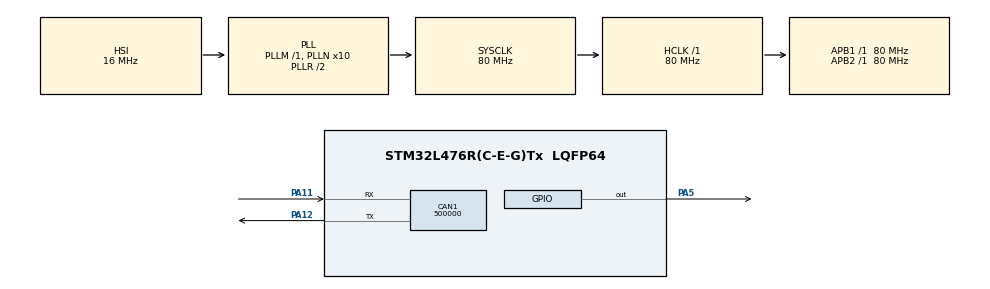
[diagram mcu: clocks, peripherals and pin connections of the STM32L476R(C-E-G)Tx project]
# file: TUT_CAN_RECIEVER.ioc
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CAN1.BS1=CAN_BS1_6TQ
CAN1.BS2=CAN_BS2_3TQ
CAN1.CalculateBaudRate=500000
CAN1.CalculateTimeBit=2000
CAN1.CalculateTimeQuantum=200.0
Mcu.Family=STM32L4
Mcu.Name=STM32L476R(C-E-G)Tx
Mcu.Package=LQFP64
NVIC.CAN1_RX0_IRQn=true\:0\:0\:false\:false\:true\:true\:true\:true
NVIC.PriorityGroup=NVIC_PRIORITYGROUP_4
PA11.Mode=CAN_Activate
PA11.Signal=CAN1_RX
PA12.Mode=CAN_Activate
PA12.Signal=CAN1_TX
PA5.Signal=GPIO_Output
PH0-OSC_IN\ (PH0).Mode=HSE-External-Oscillator
PH0-OSC_IN\ (PH0).Signal=RCC_OSC_IN
PH1-OSC_OUT\ (PH1).Mode=HSE-External-Oscillator
PH1-OSC_OUT\ (PH1).Signal=RCC_OSC_OUT
ProjectManager.HeapSize=0x200
ProjectManager.StackSize=0x400
ProjectManager.TargetToolchain=STM32CubeIDE
RCC.ADCFreq_Value=64000000
RCC.AHBFreq_Value=80000000
RCC.APB1Freq_Value=80000000
RCC.APB1TimFreq_Value=80000000
RCC.APB2Freq_Value=80000000
RCC.APB2TimFreq_Value=80000000
RCC.CortexFreq_Value=80000000
RCC.HCLKFreq_Value=80000000
RCC.HSE_VALUE=8000000
RCC.HSI_VALUE=16000000
RCC.MSI_VALUE=4000000
RCC.PLLN=10
RCC.PLLSourceVirtual=RCC_PLLSOURCE_HSI
RCC.PREFETCH_ENABLE=1
RCC.SYSCLKFreq_VALUE=80000000
RCC.SYSCLKSource=RCC_SYSCLKSOURCE_PLLCLK
RCC.USBFreq_Value=64000000
RCC.VCOOutputFreq_Value=160000000
board=NUCLEO-L476RG

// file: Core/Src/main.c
/* USER CODE BEGIN Header */
/**
  ******************************************************************************
  * @file           : main.c
  * @brief          : Main program body
  ******************************************************************************
  * @attention
  *
  * Copyright (c) 2023 STMicroelectronics.
  * All rights reserved.
  *
  * This software is licensed under terms that can be found in the LICENSE file
  * in the root directory of this software component.
  * If no LICENSE file comes with this software, it is provided AS-IS.
  *
  ******************************************************************************
  */
/* USER CODE END Header */
#include "main.h"

CAN_HandleTypeDef hcan1;

void SystemClock_Config(void);
static void MX_GPIO_Init(void);
static void MX_CAN1_Init(void);

/* USER CODE BEGIN 0 */

CAN_TxHeaderTypeDef TxHeader;
CAN_RxHeaderTypeDef RxHeader;

uint8_t TxData[8];
uint8_t RxData[8];

uint32_t TxMailbox;

int datacheck = 0;

void HAL_CAN_RxFifo0MsgPendingCallback(CAN_HandleTypeDef *hcan)
{
	HAL_CAN_GetRxMessage(hcan, CAN_RX_FIFO0, &RxHeader, RxData);
	if (RxHeader.DLC == 2)
	{
		datacheck = 1;
	}
}

/* USER CODE END 0 */

int main(void)
{

  /* MCU Configuration--------------------------------------------------------*/

  /* Reset of all peripherals, Initializes the Flash interface and the Systick. */
  HAL_Init();

  /* Configure the system clock */
  SystemClock_Config();

  /* Initialize all configured peripherals */
  MX_GPIO_Init();
  MX_CAN1_Init();
  /* USER CODE BEGIN 2 */

  HAL_CAN_Start(&hcan1);

  // Activate the notification
  HAL_CAN_ActivateNotification(&hcan1, CAN_IT_RX_FIFO0_MSG_PENDING);

  TxHeader.DLC = 2;  // data length
  TxHeader.IDE = CAN_ID_STD;
  TxHeader.RTR = CAN_RTR_DATA;
  TxHeader.StdId = 0x103;  // ID

  /* USER CODE END 2 */

  /* Infinite loop */
  while (1)
  {
	  if (datacheck)
	  {
		  // blink the LED
		  for (int i=0; i<RxData[1]; i++)
		  {
			  HAL_GPIO_TogglePin(GPIOA, GPIO_PIN_5);
			  HAL_Delay(RxData[0]);
		  }

		  datacheck = 0;

			TxData[0] = 50;   // ms Delay
			TxData[1] = 20;    // loop rep

			HAL_CAN_AddTxMessage(&hcan1, &TxHeader, TxData, &TxMailbox);
	  }
  }
}

void SystemClock_Config(void)
{
  RCC_OscInitTypeDef RCC_OscInitStruct = {0};
  RCC_ClkInitTypeDef RCC_ClkInitStruct = {0};

  /** Configure the main internal regulator output voltage
  */
  if (HAL_PWREx_ControlVoltageScaling(PWR_REGULATOR_VOLTAGE_SCALE1) != HAL_OK)
  {
    Error_Handler();
  }

  /** Initializes the RCC Oscillators according to the specified parameters
  * in the RCC_OscInitTypeDef structure.
  */
  RCC_OscInitStruct.OscillatorType = RCC_OSCILLATORTYPE_HSI;
  RCC_OscInitStruct.HSIState = RCC_HSI_ON;
  RCC_OscInitStruct.HSICalibrationValue = RCC_HSICALIBRATION_DEFAULT;
  RCC_OscInitStruct.PLL.PLLState = RCC_PLL_ON;
  RCC_OscInitStruct.PLL.PLLSource = RCC_PLLSOURCE_HSI;
  RCC_OscInitStruct.PLL.PLLM = 1;
  RCC_OscInitStruct.PLL.PLLN = 10;
  RCC_OscInitStruct.PLL.PLLP = RCC_PLLP_DIV7;
  RCC_OscInitStruct.PLL.PLLQ = RCC_PLLQ_DIV2;
  RCC_OscInitStruct.PLL.PLLR = RCC_PLLR_DIV2;
  if (HAL_RCC_OscConfig(&RCC_OscInitStruct) != HAL_OK)
  {
    Error_Handler();
  }

  /** Initializes the CPU, AHB and APB buses clocks
  */
  RCC_ClkInitStruct.ClockType = RCC_CLOCKTYPE_HCLK|RCC_CLOCKTYPE_SYSCLK
                              |RCC_CLOCKTYPE_PCLK1|RCC_CLOCKTYPE_PCLK2;
  RCC_ClkInitStruct.SYSCLKSource = RCC_SYSCLKSOURCE_PLLCLK;
  RCC_ClkInitStruct.AHBCLKDivider = RCC_SYSCLK_DIV1;
  RCC_ClkInitStruct.APB1CLKDivider = RCC_HCLK_DIV1;
  RCC_ClkInitStruct.APB2CLKDivider = RCC_HCLK_DIV1;

  if (HAL_RCC_ClockConfig(&RCC_ClkInitStruct, FLASH_LATENCY_4) != HAL_OK)
  {
    Error_Handler();
  }
}

static void MX_CAN1_Init(void)
{

  hcan1.Instance = CAN1;
  hcan1.Init.Prescaler = 16;
  hcan1.Init.Mode = CAN_MODE_NORMAL;
  hcan1.Init.SyncJumpWidth = CAN_SJW_1TQ;
  hcan1.Init.TimeSeg1 = CAN_BS1_6TQ;
  hcan1.Init.TimeSeg2 = CAN_BS2_3TQ;
  hcan1.Init.TimeTriggeredMode = DISABLE;
  hcan1.Init.AutoBusOff = DISABLE;
  hcan1.Init.AutoWakeUp = DISABLE;
  hcan1.Init.AutoRetransmission = DISABLE;
  hcan1.Init.ReceiveFifoLocked = DISABLE;
  hcan1.Init.TransmitFifoPriority = DISABLE;
  if (HAL_CAN_Init(&hcan1) != HAL_OK)
  {
    Error_Handler();
  }
  /* USER CODE BEGIN CAN1_Init 2 */

  CAN_FilterTypeDef canfilterconfig;

  canfilterconfig.FilterActivation = CAN_FILTER_ENABLE;
  canfilterconfig.FilterBank = 10;  // which filter bank to use from the assigned ones
  canfilterconfig.FilterFIFOAssignment = CAN_FILTER_FIFO0;
  canfilterconfig.FilterIdHigh = 0x446<<5;
  canfilterconfig.FilterIdLow = 0;
  canfilterconfig.FilterMaskIdHigh = 0x103<<5;
  canfilterconfig.FilterMaskIdLow = 0x0000;
  canfilterconfig.FilterMode = CAN_FILTERMODE_IDMASK;
  canfilterconfig.FilterScale = CAN_FILTERSCALE_32BIT;
  canfilterconfig.SlaveStartFilterBank = 0;  // how many filters to assign to the CAN1 (master can)

  HAL_CAN_ConfigFilter(&hcan1, &canfilterconfig);
  /* USER CODE END CAN1_Init 2 */

}

static void MX_GPIO_Init(void)
{
  GPIO_InitTypeDef GPIO_InitStruct = {0};

  /* GPIO Ports Clock Enable */
  __HAL_RCC_GPIOH_CLK_ENABLE();
  __HAL_RCC_GPIOA_CLK_ENABLE();

  /*Configure GPIO pin Output Level */
  HAL_GPIO_WritePin(GPIOA, GPIO_PIN_5, GPIO_PIN_RESET);

  /*Configure GPIO pin : PA5 */
  GPIO_InitStruct.Pin = GPIO_PIN_5;
  GPIO_InitStruct.Mode = GPIO_MODE_OUTPUT_PP;
  GPIO_InitStruct.Pull = GPIO_NOPULL;
  GPIO_InitStruct.Speed = GPIO_SPEED_FREQ_LOW;
  HAL_GPIO_Init(GPIOA, &GPIO_InitStruct);

}

void Error_Handler(void)
{
  __disable_irq();
  while (1)
  {
  }
}
